# STM32H723 register map
File version: 1.6
CPU: CM7 r0p1, little endian, MPU, FPU, 4 interrupt priority bits
Registers are 32-bit, read-write, reset 0x0 unless marked. A register's access mark holds for its fields unless they carry their own. Offsets are from the block's base; [hi:lo] are bit positions; {n}, {i} and the like mark numbered series; 'fields as' and 'values as' point back to an identical list.

## RCC — Reset and clock control
Base 0x58024400
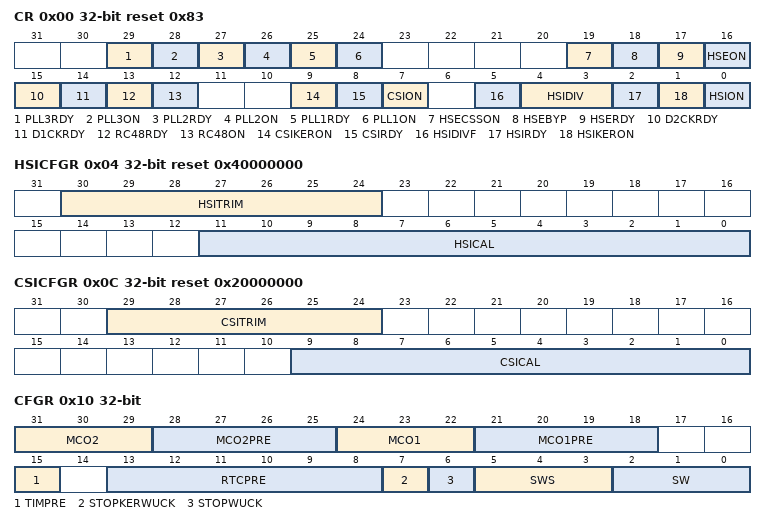
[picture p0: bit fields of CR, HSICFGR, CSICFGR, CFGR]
0x00 CR reset 0x83 — clock control register
  [29] PLL3RDY — PLL3 clock ready flag
  [28] PLL3ON — PLL3 enable
  [27] PLL2RDY — PLL2 clock ready flag
  [26] PLL2ON — PLL2 enable
  [25] PLL1RDY — PLL1 clock ready flag
  [24] PLL1ON — PLL1 enable
  [19] HSECSSON — HSE Clock Security System enable
  [18] HSEBYP — HSE clock bypass
  [17] HSERDY — HSE clock ready flag
  [16] HSEON — HSE clock enable
  [15] D2CKRDY — D2 domain clocks ready flag
  [14] D1CKRDY — D1 domain clocks ready flag
  [13] RC48RDY — RC48 clock ready flag
  [12] RC48ON — RC48 clock enable
  [9] CSIKERON — CSI clock enable in Stop mode
  [8] CSIRDY — CSI clock ready flag
  [7] CSION — CSI clock enable
  [5] HSIDIVF — HSI divider flag
  [4:3] HSIDIV — HSI clock divider
  [2] HSIRDY — HSI clock ready flag
  [1] HSIKERON — High Speed Internal clock enable in Stop mode
  [0] HSION — Internal high-speed clock enable
0x04 HSICFGR access per field reset 0x40000000 (reset mask 0xFFFFF000) — RCC HSI calibration register
  [30:24] HSITRIM rw — HSI clock trimming Set by software to adjust calibration. HSITRIM field is added to the engineering option bytes loaded during reset phase (FLASH_HSI_opt) in order to form the calibration trimming value. HSICALÂ =Â HSITRIMÂ +Â FLASH_HSI_opt. Note: The reset value of the field is 0x40.
  [11:0] HSICAL ro — HSI clock calibration Set by hardware by option byte loading during system reset nreset. Adjusted by software through trimming bits HSITRIM. This field represents the sum of engineering option byte calibration value and HSITRIM bits value.
0x08 CRRCR ro (reset mask 0xFFFFF000) — RCC clock recovery RC register
  [9:0] HSI48CAL — Internal RC 48 MHz clock calibration Set by hardware by option byte loading during system reset nreset. Read-only.
0x0C CSICFGR access per field reset 0x20000000 (reset mask 0xFFFFF000) — RCC CSI calibration register
  [29:24] CSITRIM rw — CSI clock trimming Set by software to adjust calibration. CSITRIM field is added to the engineering option bytes loaded during reset phase (FLASH_CSI_opt) in order to form the calibration trimming value. CSICALÂ =Â CSITRIMÂ +Â FLASH_CSI_opt. Note: The reset value of the field is 0x20.
  [9:0] CSICAL ro — CSI clock calibration Set by hardware by option byte loading during system reset nreset. Adjusted by software through trimming bits CSITRIM. This field represents the sum of engineering option byte calibration value and CSITRIM bits value.
0x10 CFGR — RCC Clock Configuration Register
  [31:29] MCO2 — Micro-controller clock output 2
  [28:25] MCO2PRE — MCO2 prescaler
  [24:22] MCO1 — Micro-controller clock output 1
  [21:18] MCO1PRE — MCO1 prescaler
  [15] TIMPRE — Timers clocks prescaler selection
  [13:8] RTCPRE — HSE division factor for RTC clock
  [7] STOPKERWUCK — Kernel clock selection after a wake up from system Stop
  [6] STOPWUCK — System clock selection after a wake up from system Stop
  [5:3] SWS — System clock switch status
  [2:0] SW — System clock switch
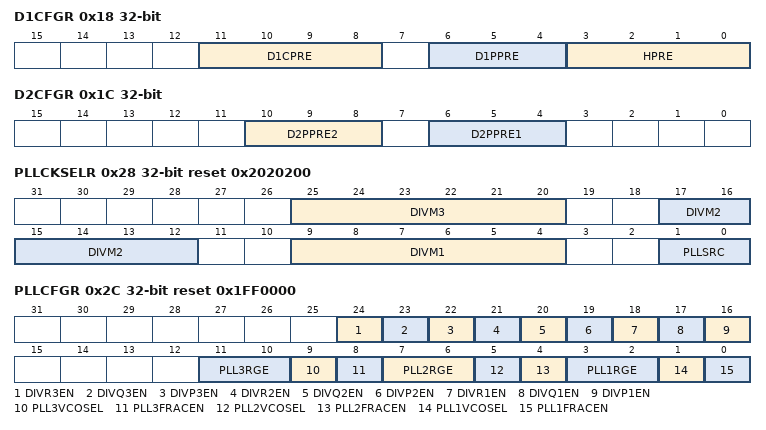
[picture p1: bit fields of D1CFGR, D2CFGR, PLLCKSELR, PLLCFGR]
0x18 D1CFGR — RCC Domain 1 Clock Configuration Register
  [11:8] D1CPRE — D1 domain Core prescaler
  [6:4] D1PPRE — D1 domain APB3 prescaler
  [3:0] HPRE — D1 domain AHB prescaler
0x1C D2CFGR — RCC Domain 2 Clock Configuration Register
  [10:8] D2PPRE2 — D2 domain APB2 prescaler
  [6:4] D2PPRE1 — D2 domain APB1 prescaler
0x20 D3CFGR — RCC Domain 3 Clock Configuration Register
  [6:4] D3PPRE — D3 domain APB4 prescaler
0x28 PLLCKSELR reset 0x2020200 — RCC PLLs Clock Source Selection Register
  [25:20] DIVM3 — Prescaler for PLL3
  [17:12] DIVM2 — Prescaler for PLL2
  [9:4] DIVM1 — Prescaler for PLL1
  [1:0] PLLSRC — DIVMx and PLLs clock source selection
0x2C PLLCFGR reset 0x1FF0000 — RCC PLLs Configuration Register
  [24] DIVR3EN — PLL3 DIVR divider output enable
  [23] DIVQ3EN — PLL3 DIVQ divider output enable
  [22] DIVP3EN — PLL3 DIVP divider output enable
  [21] DIVR2EN — PLL2 DIVR divider output enable
  [20] DIVQ2EN — PLL2 DIVQ divider output enable
  [19] DIVP2EN — PLL2 DIVP divider output enable
  [18] DIVR1EN — PLL1 DIVR divider output enable
  [17] DIVQ1EN — PLL1 DIVQ divider output enable
  [16] DIVP1EN — PLL1 DIVP divider output enable
  [11:10] PLL3RGE — PLL3 input frequency range
  [9] PLL3VCOSEL — PLL3 VCO selection
  [8] PLL3FRACEN — PLL3 fractional latch enable
  [7:6] PLL2RGE — PLL2 input frequency range
  [5] PLL2VCOSEL — PLL2 VCO selection
  [4] PLL2FRACEN — PLL2 fractional latch enable
  [3:2] PLL1RGE — PLL1 input frequency range
  [1] PLL1VCOSEL — PLL1 VCO selection
  [0] PLL1FRACEN — PLL1 fractional latch enable
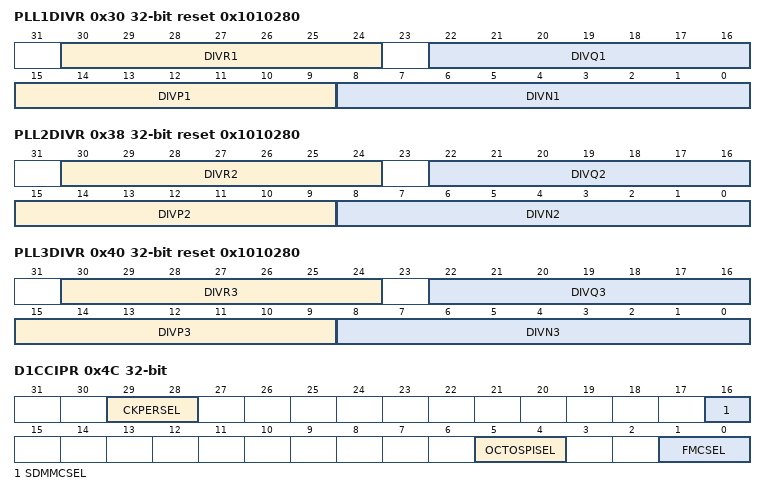
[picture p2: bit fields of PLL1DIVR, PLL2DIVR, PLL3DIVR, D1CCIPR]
0x30 PLL1DIVR reset 0x1010280 — RCC PLL1 Dividers Configuration Register
  [30:24] DIVR1 — PLL1 DIVR division factor
  [22:16] DIVQ1 — PLL1 DIVQ division factor
  [15:9] DIVP1 — PLL1 DIVP division factor
  [8:0] DIVN1 — Multiplication factor for PLL1 VCO
0x34 PLL1FRACR — RCC PLL1 Fractional Divider Register
  [15:3] FRACN1 — Fractional part of the multiplication factor for PLL1 VCO
0x38 PLL2DIVR reset 0x1010280 — RCC PLL2 Dividers Configuration Register
  [30:24] DIVR2 — PLL1 DIVR division factor
  [22:16] DIVQ2 — PLL1 DIVQ division factor
  [15:9] DIVP2 — PLL1 DIVP division factor
  [8:0] DIVN2 — Multiplication factor for PLL1 VCO
0x3C PLL2FRACR — RCC PLL2 Fractional Divider Register
  [15:3] FRACN2 — Fractional part of the multiplication factor for PLL VCO
0x40 PLL3DIVR reset 0x1010280 — RCC PLL3 Dividers Configuration Register
  [30:24] DIVR3 — PLL DIVR division factor
  [22:16] DIVQ3 — PLL DIVQ division factor
  [15:9] DIVP3 — PLL DIVP division factor
  [8:0] DIVN3 — Multiplication factor for PLL1 VCO
0x44 PLL3FRACR — RCC PLL3 Fractional Divider Register
  [15:3] FRACN3 — Fractional part of the multiplication factor for PLL3 VCO
0x4C D1CCIPR — RCC Domain 1 Kernel Clock Configuration Register
  [29:28] CKPERSEL — per_ck clock source selection
  [16] SDMMCSEL — SDMMC kernel clock source selection
  [5:4] OCTOSPISEL — QUADSPI kernel clock source selection
  [1:0] FMCSEL — FMC kernel clock source selection
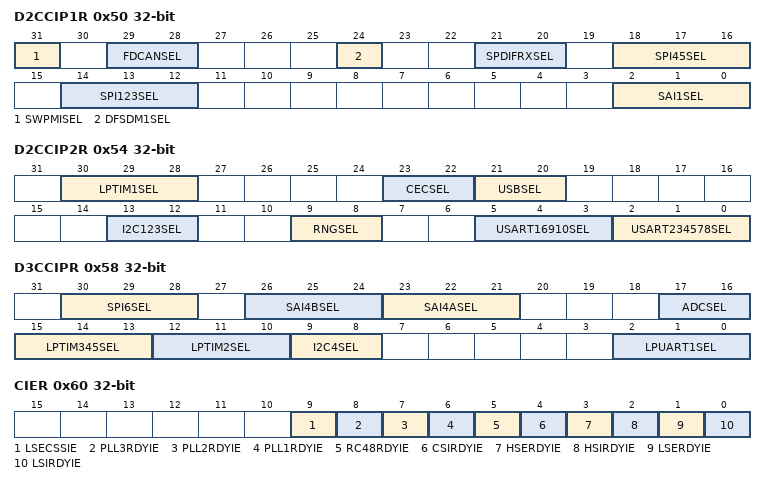
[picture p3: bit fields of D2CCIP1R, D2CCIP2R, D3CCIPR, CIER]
0x50 D2CCIP1R — RCC Domain 2 Kernel Clock Configuration Register
  [31] SWPMISEL — SWPMI kernel clock source selection
  [29:28] FDCANSEL — FDCAN kernel clock source selection
  [24] DFSDM1SEL — DFSDM1 kernel Clk clock source selection
  [21:20] SPDIFRXSEL — SPDIFRX kernel clock source selection
  [18:16] SPI45SEL — SPI4 and 5 kernel clock source selection
  [14:12] SPI123SEL — SPI/I2S1,2 and 3 kernel clock source selection
  [2:0] SAI1SEL — SAI1 and DFSDM1 kernel Aclk clock source selection
0x54 D2CCIP2R — RCC Domain 2 Kernel Clock Configuration Register
  [30:28] LPTIM1SEL — LPTIM1 kernel clock source selection
  [23:22] CECSEL — HDMI-CEC kernel clock source selection
  [21:20] USBSEL — USBOTG 1 and 2 kernel clock source selection
  [13:12] I2C123SEL — I2C1,2,3 kernel clock source selection
  [9:8] RNGSEL — RNG kernel clock source selection
  [5:3] USART16910SEL — USART1 and 6 kernel clock source selection
  [2:0] USART234578SEL — USART2/3, UART4,5, 7/8 (APB1) kernel clock source selection
0x58 D3CCIPR — RCC Domain 3 Kernel Clock Configuration Register
  [30:28] SPI6SEL — SPI6 kernel clock source selection
  [26:24] SAI4BSEL — Sub-Block B of SAI4 kernel clock source selection
  [23:21] SAI4ASEL — Sub-Block A of SAI4 kernel clock source selection
  [17:16] ADCSEL — SAR ADC kernel clock source selection
  [15:13] LPTIM345SEL — LPTIM3,4,5 kernel clock source selection
  [12:10] LPTIM2SEL — LPTIM2 kernel clock source selection
  [9:8] I2C4SEL — I2C4 kernel clock source selection
  [2:0] LPUART1SEL — LPUART1 kernel clock source selection
0x60 CIER — RCC Clock Source Interrupt Enable Register
  [9] LSECSSIE — LSE clock security system Interrupt Enable
  [8] PLL3RDYIE — PLL3 ready Interrupt Enable
  [7] PLL2RDYIE — PLL2 ready Interrupt Enable
  [6] PLL1RDYIE — PLL1 ready Interrupt Enable
  [5] RC48RDYIE — RC48 ready Interrupt Enable
  [4] CSIRDYIE — CSI ready Interrupt Enable
  [3] HSERDYIE — HSE ready Interrupt Enable
  [2] HSIRDYIE — HSI ready Interrupt Enable
  [1] LSERDYIE — LSE ready Interrupt Enable
  [0] LSIRDYIE — LSI ready Interrupt Enable
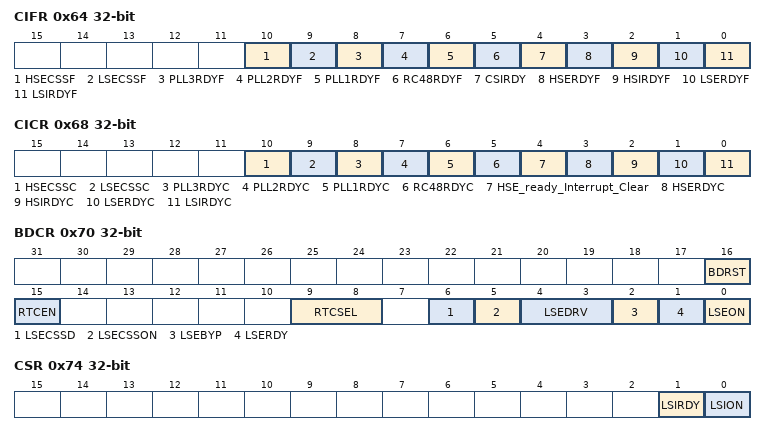
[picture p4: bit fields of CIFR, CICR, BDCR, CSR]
0x64 CIFR — RCC Clock Source Interrupt Flag Register
  [10] HSECSSF — HSE clock security system Interrupt Flag
  [9] LSECSSF — LSE clock security system Interrupt Flag
  [8] PLL3RDYF — PLL3 ready Interrupt Flag
  [7] PLL2RDYF — PLL2 ready Interrupt Flag
  [6] PLL1RDYF — PLL1 ready Interrupt Flag
  [5] RC48RDYF — RC48 ready Interrupt Flag
  [4] CSIRDY — CSI ready Interrupt Flag
  [3] HSERDYF — HSE ready Interrupt Flag
  [2] HSIRDYF — HSI ready Interrupt Flag
  [1] LSERDYF — LSE ready Interrupt Flag
  [0] LSIRDYF — LSI ready Interrupt Flag
0x68 CICR — RCC Clock Source Interrupt Clear Register
  [10] HSECSSC — HSE clock security system Interrupt Clear
  [9] LSECSSC — LSE clock security system Interrupt Clear
  [8] PLL3RDYC — PLL3 ready Interrupt Clear
  [7] PLL2RDYC — PLL2 ready Interrupt Clear
  [6] PLL1RDYC — PLL1 ready Interrupt Clear
  [5] RC48RDYC — RC48 ready Interrupt Clear
  [4] HSE_ready_Interrupt_Clear — CSI ready Interrupt Clear
  [3] HSERDYC — HSE ready Interrupt Clear
  [2] HSIRDYC — HSI ready Interrupt Clear
  [1] LSERDYC — LSE ready Interrupt Clear
  [0] LSIRDYC — LSI ready Interrupt Clear
0x70 BDCR — RCC Backup Domain Control Register
  [16] BDRST — Backup domain software reset
  [15] RTCEN — RTC clock enable
  [9:8] RTCSEL — RTC clock source selection
  [6] LSECSSD — LSE clock security system failure detection
  [5] LSECSSON — LSE clock security system enable
  [4:3] LSEDRV — LSE oscillator driving capability
  [2] LSEBYP — LSE oscillator bypass
  [1] LSERDY — LSE oscillator ready
  [0] LSEON — LSE oscillator enabled
0x74 CSR — RCC Clock Control and Status Register
  [1] LSIRDY — LSI oscillator ready
  [0] LSION — LSI oscillator enable
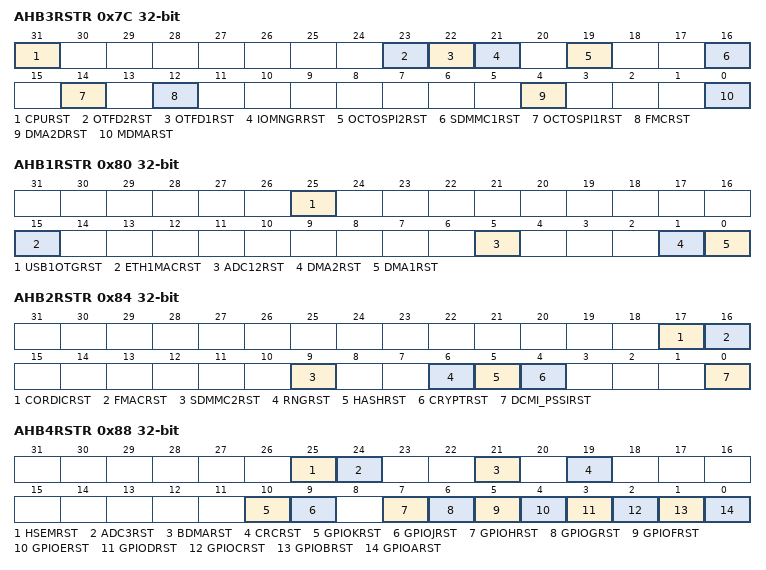
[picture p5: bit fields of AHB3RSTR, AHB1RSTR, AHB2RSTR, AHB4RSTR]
0x7C AHB3RSTR — RCC AHB3 Reset Register
  [31] CPURST — CPU reset
  [23] OTFD2RST — OTFD2 reset Set and reset by software Take care that resetting the OTFD means loosing the decryption key loaded during secure boot.
  [22] OTFD1RST — OTFD1 reset Set and reset by software Take care that resetting the OTFD means loosing the decryption key loaded during secure boot.
  [21] IOMNGRRST — OCTOSPIM reset Set and reset by software
  [19] OCTOSPI2RST — OCTOSPI2 and OCTOSPI2 delay block reset Set and reset by software
  [16] SDMMC1RST — SDMMC1 and SDMMC1 delay block reset
  [14] OCTOSPI1RST — QUADSPI and QUADSPI delay block reset
  [12] FMCRST — FMC block reset
  [4] DMA2DRST — DMA2D block reset
  [0] MDMARST — MDMA block reset
0x80 AHB1RSTR — RCC AHB1 Peripheral Reset Register
  [25] USB1OTGRST — USB1OTG block reset
  [15] ETH1MACRST — ETH1MAC block reset
  [5] ADC12RST — ADC1&2 block reset
  [1] DMA2RST — DMA2 block reset
  [0] DMA1RST — DMA1 block reset
0x84 AHB2RSTR — RCC AHB2 Peripheral Reset Register
  [17] CORDICRST — CORDIC coprocessor block reset
  [16] FMACRST — FMAC reset
  [9] SDMMC2RST — SDMMC2 and SDMMC2 Delay block reset
  [6] RNGRST — Random Number Generator block reset
  [5] HASHRST — Hash block reset
  [4] CRYPTRST — Cryptography block reset
  [0] DCMI_PSSIRST
0x88 AHB4RSTR — RCC AHB4 Peripheral Reset Register
  [25] HSEMRST — HSEM block reset
  [24] ADC3RST — ADC3 block reset
  [21] BDMARST — BDMA block reset
  [19] CRCRST — CRC block reset
  [10] GPIOKRST — GPIO block reset
  [9] GPIOJRST — GPIO block reset
  [7] GPIOHRST — GPIO block reset
  [6] GPIOGRST — GPIO block reset
  [5] GPIOFRST — GPIO block reset
  [4] GPIOERST — GPIO block reset
  [3] GPIODRST — GPIO block reset
  [2] GPIOCRST — GPIO block reset
  [1] GPIOBRST — GPIO block reset
  [0] GPIOARST — GPIO block reset
0x8C APB3RSTR — RCC APB3 Peripheral Reset Register
  [3] LTDCRST — LTDC block reset
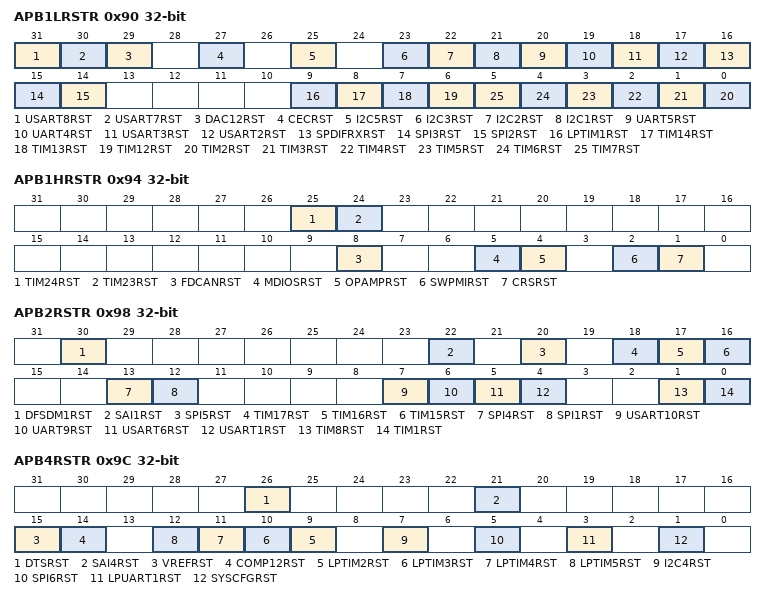
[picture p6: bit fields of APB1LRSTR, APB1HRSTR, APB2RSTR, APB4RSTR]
0x90 APB1LRSTR — RCC APB1 Peripheral Reset Register
  [31] USART8RST — USART8 block reset
  [30] USART7RST — USART7 block reset
  [29] DAC12RST — DAC1 and 2 Blocks Reset
  [27] CECRST — HDMI-CEC block reset
  [25] I2C5RST — I2C5 block reset
  [23] I2C3RST — I2C3 block reset
  [22] I2C2RST — I2C2 block reset
  [21] I2C1RST — I2C1 block reset
  [20] UART5RST — UART5 block reset
  [19] UART4RST — UART4 block reset
  [18] USART3RST — USART3 block reset
  [17] USART2RST — USART2 block reset
  [16] SPDIFRXRST — SPDIFRX block reset
  [15] SPI3RST — SPI3 block reset
  [14] SPI2RST — SPI2 block reset
  [9] LPTIM1RST — TIM block reset
  [8] TIM14RST — TIM block reset
  [7] TIM13RST — TIM block reset
  [6] TIM12RST — TIM block reset
  [n-2] TIM{n}RST (n=2..7) — TIM block reset
0x94 APB1HRSTR — RCC APB1 Peripheral Reset Register
  [25] TIM24RST — TIM24 block resett
  [24] TIM23RST — TIM23 block reset
  [8] FDCANRST — FDCAN block reset
  [5] MDIOSRST — MDIOS block reset
  [4] OPAMPRST — OPAMP block reset
  [2] SWPMIRST — SWPMI block reset
  [1] CRSRST — Clock Recovery System reset
0x98 APB2RSTR — RCC APB2 Peripheral Reset Register
  [30] DFSDM1RST — DFSDM1 block reset Set and reset by software.
  [22] SAI1RST — SAI1 block reset
  [20] SPI5RST — SPI5 block reset
  [18] TIM17RST — TIM17 block reset
  [17] TIM16RST — TIM16 block reset
  [16] TIM15RST — TIM15 block reset
  [13] SPI4RST — SPI4 block reset
  [12] SPI1RST — SPI1 block reset
  [7] USART10RST — USART10 block reset Set and reset by software.
  [6] UART9RST — UART9 block reset Set and reset by software.
  [5] USART6RST — USART6 block reset
  [4] USART1RST — USART1 block reset
  [1] TIM8RST — TIM8 block reset
  [0] TIM1RST — TIM1 block reset
0x9C APB4RSTR — RCC APB4 Peripheral Reset Register
  [26] DTSRST — Digital temperature sensor block reset Set and reset by software.
  [21] SAI4RST — SAI4 block reset
  [15] VREFRST — VREF block reset
  [14] COMP12RST — COMP12 Blocks Reset
  [n+7] LPTIM{n}RST (n=2..5) — LPTIM{n} block reset
  [7] I2C4RST — I2C4 block reset
  [5] SPI6RST — SPI6 block reset
  [3] LPUART1RST — LPUART1 block reset
  [1] SYSCFGRST — SYSCFG block reset
0xA0 GCR — RCC Global Control Register
  [0] WW1RSC — WWDG1 reset scope control
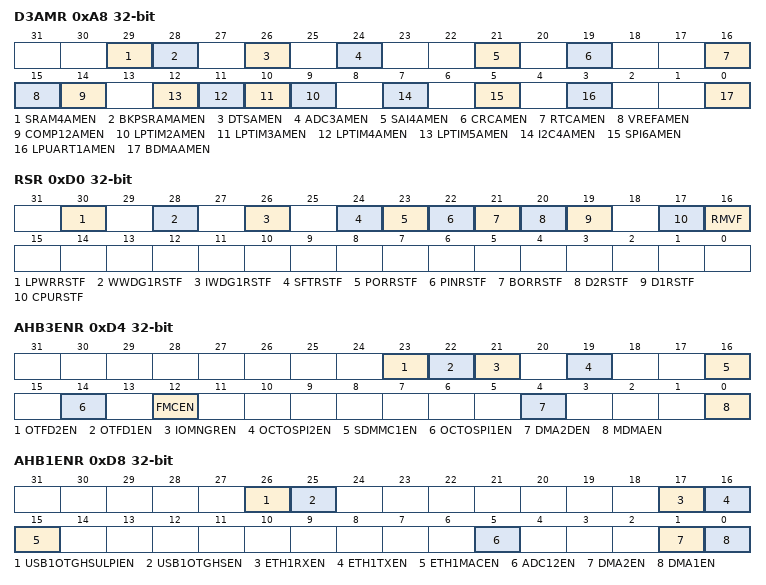
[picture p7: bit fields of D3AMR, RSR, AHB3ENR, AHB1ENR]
0xA8 D3AMR — RCC D3 Autonomous mode Register
  [29] SRAM4AMEN — SRAM4 Autonomous mode enable
  [28] BKPSRAMAMEN — Backup RAM Autonomous mode enable
  [26] DTSAMEN — Digital temperature sensor Autonomous mode enable Set and reset by software. Refer to for additional information.
  [24] ADC3AMEN — ADC3 Autonomous mode enable
  [21] SAI4AMEN — SAI4 Autonomous mode enable
  [19] CRCAMEN — CRC Autonomous mode enable
  [16] RTCAMEN — RTC Autonomous mode enable
  [15] VREFAMEN — VREF Autonomous mode enable
  [14] COMP12AMEN — COMP12 Autonomous mode enable
  [n+7] LPTIM{n}AMEN (n=2..5) — LPTIM{n} Autonomous mode enable
  [7] I2C4AMEN — I2C4 Autonomous mode enable
  [5] SPI6AMEN — SPI6 Autonomous mode enable
  [3] LPUART1AMEN — LPUART1 Autonomous mode enable
  [0] BDMAAMEN — BDMA and DMAMUX Autonomous mode enable
0xD0 RSR — RCC Reset Status Register
  [30] LPWRRSTF — Reset due to illegal D1 DStandby or CPU CStop flag
  [28] WWDG1RSTF — Window Watchdog reset flag
  [26] IWDG1RSTF — Independent Watchdog reset flag
  [24] SFTRSTF — System reset from CPU reset flag
  [23] PORRSTF — POR/PDR reset flag
  [22] PINRSTF — Pin reset flag (NRST)
  [21] BORRSTF — BOR reset flag
  [20] D2RSTF — D2 domain power switch reset flag
  [19] D1RSTF — D1 domain power switch reset flag
  [17] CPURSTF — CPU reset flag
  [16] RMVF — Remove reset flag
0xD4 AHB3ENR — RCC AHB3 Clock Register
  [23] OTFD2EN — OTFD2 clock enable Set and reset by software.
  [22] OTFD1EN — OTFD1 clock enable Set and reset by software.
  [21] IOMNGREN — OCTOSPIM clock enable Set and reset by software.
  [19] OCTOSPI2EN — OCTOSPI2 clock enable Set and reset by software.
  [16] SDMMC1EN — SDMMC1 and SDMMC1 Delay Clock Enable
  [14] OCTOSPI1EN — OCTOSPI1 and OCTOSPI1 delay clock enable
  [12] FMCEN — FMC Peripheral Clocks Enable
  [4] DMA2DEN — DMA2D Peripheral Clock Enable
  [0] MDMAEN — MDMA Peripheral Clock Enable
0xD8 AHB1ENR — RCC AHB1 Clock Register
  [26] USB1OTGHSULPIEN — USB_PHY1 Clocks Enable
  [25] USB1OTGHSEN — USB1OTG Peripheral Clocks Enable
  [17] ETH1RXEN — Ethernet Reception Clock Enable
  [16] ETH1TXEN — Ethernet Transmission Clock Enable
  [15] ETH1MACEN — Ethernet MAC bus interface Clock Enable
  [5] ADC12EN — ADC1/2 Peripheral Clocks Enable
  [1] DMA2EN — DMA2 Clock Enable
  [0] DMA1EN — DMA1 Clock Enable
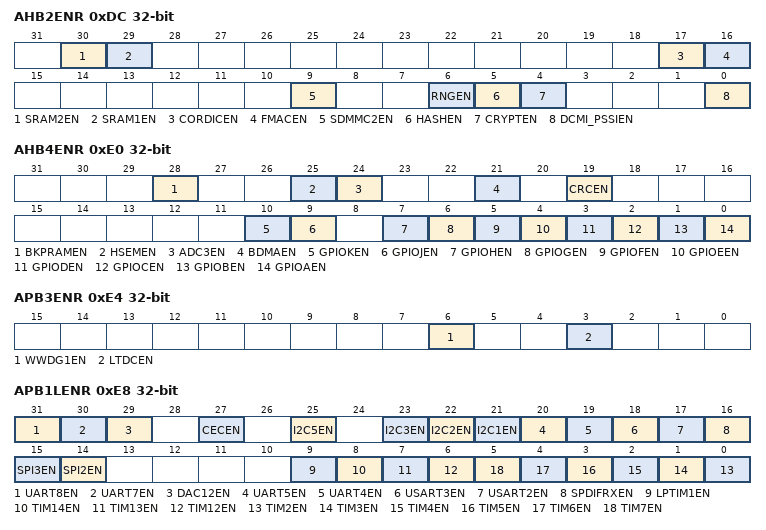
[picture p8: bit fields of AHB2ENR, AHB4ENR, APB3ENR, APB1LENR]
0xDC AHB2ENR — RCC AHB2 Clock Register
  [30] SRAM2EN — SRAM2 block enable
  [29] SRAM1EN — SRAM1 block enable
  [17] CORDICEN — CORDIC clock enable
  [16] FMACEN — FMAC clock enable
  [9] SDMMC2EN — SDMMC2 and SDMMC2 delay clock enable
  [6] RNGEN — RNG peripheral clocks enable
  [5] HASHEN — HASH peripheral clock enable
  [4] CRYPTEN — CRYPT peripheral clock enable
  [0] DCMI_PSSIEN — CAMITF peripheral clock enable
0xE0 AHB4ENR — RCC AHB4 Clock Register
  [28] BKPRAMEN — Backup RAM Clock Enable
  [25] HSEMEN — HSEM peripheral clock enable
  [24] ADC3EN — ADC3 Peripheral Clocks Enable
  [21] BDMAEN — BDMA and DMAMUX2 Clock Enable
  [19] CRCEN — CRC peripheral clock enable
  [10] GPIOKEN — 0GPIO peripheral clock enable
  [9] GPIOJEN — 0GPIO peripheral clock enable
  [7] GPIOHEN — 0GPIO peripheral clock enable
  [6] GPIOGEN — 0GPIO peripheral clock enable
  [5] GPIOFEN — 0GPIO peripheral clock enable
  [4] GPIOEEN — 0GPIO peripheral clock enable
  [3] GPIODEN — 0GPIO peripheral clock enable
  [2] GPIOCEN — 0GPIO peripheral clock enable
  [1] GPIOBEN — 0GPIO peripheral clock enable
  [0] GPIOAEN — 0GPIO peripheral clock enable
0xE4 APB3ENR — RCC APB3 Clock Register
  [6] WWDG1EN — WWDG1 Clock Enable
  [3] LTDCEN — LTDC peripheral clock enable
0xE8 APB1LENR — RCC APB1 Clock Register
  [31] UART8EN — UART8 Peripheral Clocks Enable
  [30] UART7EN — UART7 Peripheral Clocks Enable
  [29] DAC12EN — DAC1 and 2 peripheral clock enable
  [27] CECEN — HDMI-CEC peripheral clock enable
  [25] I2C5EN — I2C5 Peripheral Clocks Enable
  [23] I2C3EN — I2C3 Peripheral Clocks Enable
  [22] I2C2EN — I2C2 Peripheral Clocks Enable
  [21] I2C1EN — I2C1 Peripheral Clocks Enable
  [20] UART5EN — UART5 Peripheral Clocks Enable
  [19] UART4EN — UART4 Peripheral Clocks Enable
  [18] USART3EN — USART3 Peripheral Clocks Enable
  [17] USART2EN — USART2 Peripheral Clocks Enable
  [16] SPDIFRXEN — SPDIFRX Peripheral Clocks Enable
  [15] SPI3EN — SPI3 Peripheral Clocks Enable
  [14] SPI2EN — SPI2 Peripheral Clocks Enable
  [9] LPTIM1EN — LPTIM1 Peripheral Clocks Enable
  [8] TIM14EN — TIM peripheral clock enable
  [7] TIM13EN — TIM peripheral clock enable
  [6] TIM12EN — TIM peripheral clock enable
  [n-2] TIM{n}EN (n=2..7) — TIM peripheral clock enable
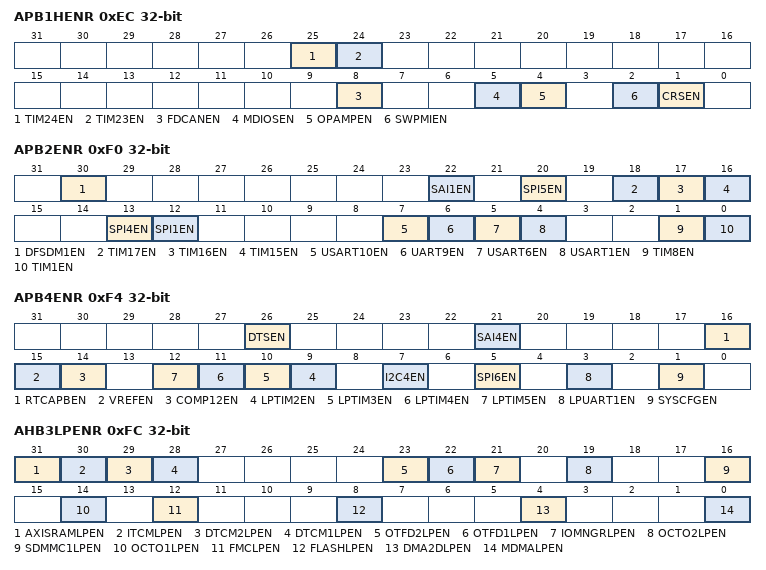
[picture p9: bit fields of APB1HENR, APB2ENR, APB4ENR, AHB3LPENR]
0xEC APB1HENR — RCC APB1 Clock Register
  [25] TIM24EN — TIM24 Peripheral Clocks Enable
  [24] TIM23EN — TIM23 Peripheral Clocks Enable
  [8] FDCANEN — FDCAN Peripheral Clocks Enable
  [5] MDIOSEN — MDIOS peripheral clock enable
  [4] OPAMPEN — OPAMP peripheral clock enable
  [2] SWPMIEN — SWPMI Peripheral Clocks Enable
  [1] CRSEN — Clock Recovery System peripheral clock enable
0xF0 APB2ENR — RCC APB2 Clock Register
  [30] DFSDM1EN — DFSDM1 peripheral clocks enable Set and reset by software. DFSDM1 peripheral clocks are the kernel clocks selected by SAI1SEL and DFSDM1SEL and provided to Aclk and clk inputs respectively,
  [22] SAI1EN — SAI1 Peripheral Clocks Enable
  [20] SPI5EN — SPI5 Peripheral Clocks Enable
  [18] TIM17EN — TIM17 peripheral clock enable
  [17] TIM16EN — TIM16 peripheral clock enable
  [16] TIM15EN — TIM15 peripheral clock enable Set and reset by software.
  [13] SPI4EN — SPI4 Peripheral Clocks Enable
  [12] SPI1EN — SPI1 Peripheral Clocks Enable
  [7] USART10EN — USART10 peripheral clocks enable Set and reset by software. The peripheral clocks of the USART10 are the kernel clock selected by USART16910SEL and provided to UCKL input, and the rcc_pclk2 bus interface clock.
  [6] UART9EN — UART9 peripheral clocks enable Set and reset by software. The peripheral clocks of the UART9 are the kernel clock selected by USART16910SEL and provided to UCKL input, and the rcc_pclk2 bus interface clock.
  [5] USART6EN — USART6 Peripheral Clocks Enable
  [4] USART1EN — USART1 Peripheral Clocks Enable
  [1] TIM8EN — TIM8 peripheral clock enable
  [0] TIM1EN — TIM1 peripheral clock enable
0xF4 APB4ENR — RCC APB4 Clock Register
  [26] DTSEN — Digital temperature sensor peripheral clock enable Set and reset by software.
  [21] SAI4EN — SAI4 Peripheral Clocks Enable
  [16] RTCAPBEN — RTC APB Clock Enable
  [15] VREFEN — VREF peripheral clock enable
  [14] COMP12EN — COMP1/2 peripheral clock enable
  [n+7] LPTIM{n}EN (n=2..5) — LPTIM{n} Peripheral Clocks Enable
  [7] I2C4EN — I2C4 Peripheral Clocks Enable
  [5] SPI6EN — SPI6 Peripheral Clocks Enable
  [3] LPUART1EN — LPUART1 Peripheral Clocks Enable
  [1] SYSCFGEN — SYSCFG peripheral clock enable
0xFC AHB3LPENR — RCC AHB3 Sleep Clock Register
  [31] AXISRAMLPEN — AXISRAM Block Clock Enable During CSleep mode
  [30] ITCMLPEN — D1ITCM Block Clock Enable During CSleep mode
  [29] DTCM2LPEN — D1 DTCM2 Block Clock Enable During CSleep mode
  [28] DTCM1LPEN — D1DTCM1 Block Clock Enable During CSleep mode
  [23] OTFD2LPEN — OTFD2 block clock enable during CSleep mode Set and reset by software.
  [22] OTFD1LPEN — OTFD1 block clock enable during CSleep mode Set and reset by software.
  [21] IOMNGRLPEN — OCTOSPIM block clock enable during CSleep mode Set and reset by software.
  [19] OCTO2LPEN — OCTOSPI2 and OCTOSPI2 delay clock enable during CSleep mode Set and reset by software.
  [16] SDMMC1LPEN — SDMMC1 and SDMMC1 Delay Clock Enable During CSleep Mode
  [14] OCTO1LPEN — QUADSPI and QUADSPI Delay Clock Enable During CSleep Mode
  [12] FMCLPEN — FMC Peripheral Clocks Enable During CSleep Mode
  [8] FLASHLPEN — Flash interface Clock Enable During CSleep Mode
  [4] DMA2DLPEN — DMA2D Clock Enable During CSleep Mode
  [0] MDMALPEN — MDMA Clock Enable During CSleep Mode
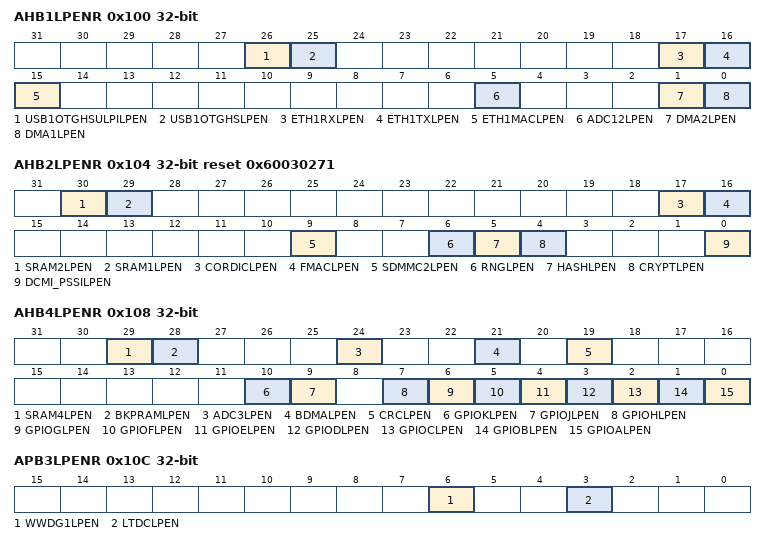
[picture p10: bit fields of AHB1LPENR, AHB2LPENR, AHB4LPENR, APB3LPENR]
0x100 AHB1LPENR — RCC AHB1 Sleep Clock Register
  [26] USB1OTGHSULPILPEN — USB_PHY1 clock enable during CSleep mode
  [25] USB1OTGHSLPEN — USB1OTG peripheral clock enable during CSleep mode
  [17] ETH1RXLPEN — Ethernet Reception Clock Enable During CSleep Mode
  [16] ETH1TXLPEN — Ethernet Transmission Clock Enable During CSleep Mode
  [15] ETH1MACLPEN — Ethernet MAC bus interface Clock Enable During CSleep Mode
  [5] ADC12LPEN — ADC1/2 Peripheral Clocks Enable During CSleep Mode
  [1] DMA2LPEN — DMA2 Clock Enable During CSleep Mode
  [0] DMA1LPEN — DMA1 Clock Enable During CSleep Mode
0x104 AHB2LPENR reset 0x60030271 — RCC AHB2 Sleep Clock Register
  [30] SRAM2LPEN — SRAM2 Clock Enable During CSleep Mode
  [29] SRAM1LPEN — SRAM1 Clock Enable During CSleep Mode
  [17] CORDICLPEN — CORDIC peripheral clock enable during CSleep mode
  [16] FMACLPEN — FMAC peripheral clock enable during CSleep mode
  [9] SDMMC2LPEN — SDMMC2 and SDMMC2 Delay Clock Enable During CSleep Mode
  [6] RNGLPEN — RNG peripheral clock enable during CSleep mode
  [5] HASHLPEN — HASH peripheral clock enable during CSleep mode
  [4] CRYPTLPEN — CRYPT peripheral clock enable during CSleep mode
  [0] DCMI_PSSILPEN
0x108 AHB4LPENR — RCC AHB4 Sleep Clock Register
  [29] SRAM4LPEN — SRAM4 Clock Enable During CSleep Mode
  [28] BKPRAMLPEN — Backup RAM Clock Enable During CSleep Mode
  [24] ADC3LPEN — ADC3 Peripheral Clocks Enable During CSleep Mode
  [21] BDMALPEN — BDMA Clock Enable During CSleep Mode
  [19] CRCLPEN — CRC peripheral clock enable during CSleep mode
  [10] GPIOKLPEN — GPIO peripheral clock enable during CSleep mode
  [9] GPIOJLPEN — GPIO peripheral clock enable during CSleep mode
  [7] GPIOHLPEN — GPIO peripheral clock enable during CSleep mode
  [6] GPIOGLPEN — GPIO peripheral clock enable during CSleep mode
  [5] GPIOFLPEN — GPIO peripheral clock enable during CSleep mode
  [4] GPIOELPEN — GPIO peripheral clock enable during CSleep mode
  [3] GPIODLPEN — GPIO peripheral clock enable during CSleep mode
  [2] GPIOCLPEN — GPIO peripheral clock enable during CSleep mode
  [1] GPIOBLPEN — GPIO peripheral clock enable during CSleep mode
  [0] GPIOALPEN — GPIO peripheral clock enable during CSleep mode
0x10C APB3LPENR — RCC APB3 Sleep Clock Register
  [6] WWDG1LPEN — WWDG1 Clock Enable During CSleep Mode
  [3] LTDCLPEN — LTDC peripheral clock enable during CSleep mode
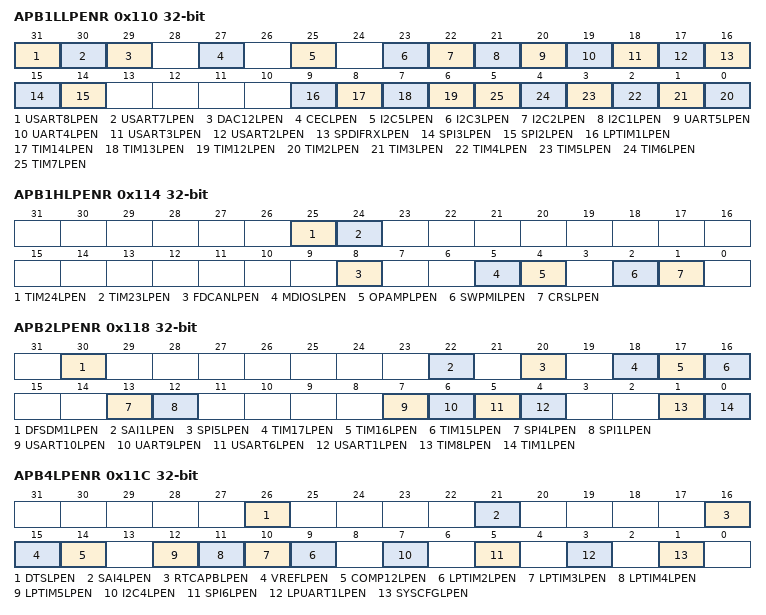
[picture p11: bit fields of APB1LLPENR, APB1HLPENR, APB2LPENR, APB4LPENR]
0x110 APB1LLPENR — RCC APB1 Low Sleep Clock Register
  [31] USART8LPEN — USART8 Peripheral Clocks Enable During CSleep Mode
  [30] USART7LPEN — USART7 Peripheral Clocks Enable During CSleep Mode
  [29] DAC12LPEN — DAC1/2 peripheral clock enable during CSleep mode
  [27] CECLPEN — CEC Peripheral Clocks Enable During CSleep Mode
  [25] I2C5LPEN — I2C5 Peripheral Clocks Enable During CSleep Mode
  [23] I2C3LPEN — I2C3 Peripheral Clocks Enable During CSleep Mode
  [22] I2C2LPEN — I2C2 Peripheral Clocks Enable During CSleep Mode
  [21] I2C1LPEN — I2C1 Peripheral Clocks Enable During CSleep Mode
  [20] UART5LPEN — UART5 Peripheral Clocks Enable During CSleep Mode
  [19] UART4LPEN — UART4 Peripheral Clocks Enable During CSleep Mode
  [18] USART3LPEN — USART3 Peripheral Clocks Enable During CSleep Mode
  [17] USART2LPEN — USART2 Peripheral Clocks Enable During CSleep Mode
  [16] SPDIFRXLPEN — SPDIFRX Peripheral Clocks Enable During CSleep Mode
  [15] SPI3LPEN — SPI3 Peripheral Clocks Enable During CSleep Mode
  [14] SPI2LPEN — SPI2 Peripheral Clocks Enable During CSleep Mode
  [9] LPTIM1LPEN — LPTIM1 Peripheral Clocks Enable During CSleep Mode
  [8] TIM14LPEN — TIM14 peripheral clock enable during CSleep mode
  [7] TIM13LPEN — TIM13 peripheral clock enable during CSleep mode
  [6] TIM12LPEN — TIM12 peripheral clock enable during CSleep mode
  [n-2] TIM{n}LPEN (n=2..7) — TIM{n} peripheral clock enable during CSleep mode
0x114 APB1HLPENR — RCC APB1 High Sleep Clock Register
  [25] TIM24LPEN — TIM24 Peripheral Clocks Enable During CSleep Mode
  [24] TIM23LPEN — TIM23 Peripheral Clocks Enable During CSleep Mode
  [8] FDCANLPEN — FDCAN Peripheral Clocks Enable During CSleep Mode
  [5] MDIOSLPEN — MDIOS peripheral clock enable during CSleep mode
  [4] OPAMPLPEN — OPAMP peripheral clock enable during CSleep mode
  [2] SWPMILPEN — SWPMI Peripheral Clocks Enable During CSleep Mode
  [1] CRSLPEN — Clock Recovery System peripheral clock enable during CSleep mode
0x118 APB2LPENR — RCC APB2 Sleep Clock Register
  [30] DFSDM1LPEN — DFSDM1 peripheral clocks enable during CSleep mode Set and reset by software. DFSDM1 peripheral clocks are the kernel clocks selected by SAI1SEL and DFSDM1SEL and provided to Aclk and clk inputs respectively, and the rcc_pclk2 bus interface clock.
  [22] SAI1LPEN — SAI1 Peripheral Clocks Enable During CSleep Mode
  [20] SPI5LPEN — SPI5 Peripheral Clocks Enable During CSleep Mode
  [18] TIM17LPEN — TIM17 peripheral clock enable during CSleep mode
  [17] TIM16LPEN — TIM16 peripheral clock enable during CSleep mode
  [16] TIM15LPEN — TIM15 peripheral clock enable during CSleep mode
  [13] SPI4LPEN — SPI4 Peripheral Clocks Enable During CSleep Mode
  [12] SPI1LPEN — SPI1 Peripheral Clocks Enable During CSleep Mode
  [7] USART10LPEN — USART10 peripheral clock enable during CSleep mode Set and reset by software. The peripheral clocks of the USART10 are the kernel clock selected by USART16910SEL and provided to usart_ker_ck input, and the rcc_pclk2 bus interface clock.
  [6] UART9LPEN — UART9 peripheral clock enable during CSleep mode Set and reset by software. The peripheral clocks of the UART9 are the kernel clock selected by USART16910SEL and provided to usart_ker_ck input, and the rcc_pclk2 bus interface clock.
  [5] USART6LPEN — USART6 Peripheral Clocks Enable During CSleep Mode
  [4] USART1LPEN — USART1 Peripheral Clocks Enable During CSleep Mode
  [1] TIM8LPEN — TIM8 peripheral clock enable during CSleep mode
  [0] TIM1LPEN — TIM1 peripheral clock enable during CSleep mode
0x11C APB4LPENR — RCC APB4 Sleep Clock Register
  [26] DTSLPEN — Digital temperature sensor peripheral clock enable during CSleep mode
  [21] SAI4LPEN — SAI4 Peripheral Clocks Enable During CSleep Mode
  [16] RTCAPBLPEN — RTC APB Clock Enable During CSleep Mode
  [15] VREFLPEN — VREF peripheral clock enable during CSleep mode
  [14] COMP12LPEN — COMP1/2 peripheral clock enable during CSleep mode
  [n+7] LPTIM{n}LPEN (n=2..5) — LPTIM{n} Peripheral Clocks Enable During CSleep Mode
  [7] I2C4LPEN — I2C4 Peripheral Clocks Enable During CSleep Mode
  [5] SPI6LPEN — SPI6 Peripheral Clocks Enable During CSleep Mode
  [3] LPUART1LPEN — LPUART1 Peripheral Clocks Enable During CSleep Mode
  [1] SYSCFGLPEN — SYSCFG peripheral clock enable during CSleep mode
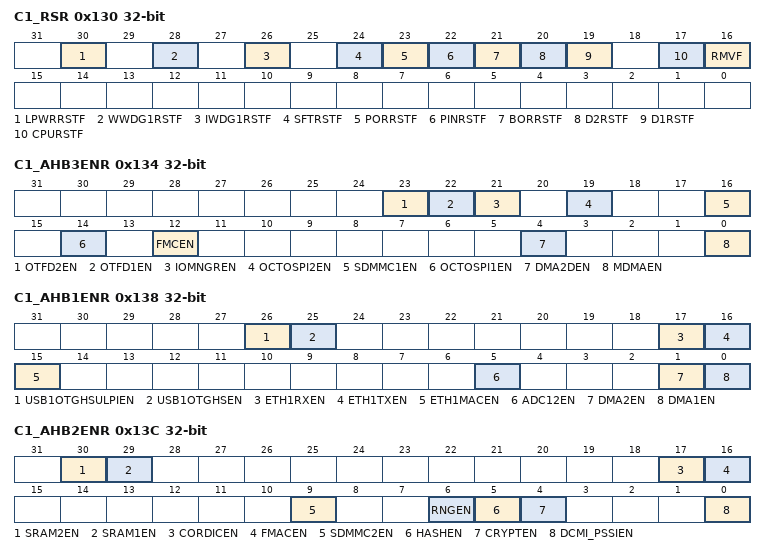
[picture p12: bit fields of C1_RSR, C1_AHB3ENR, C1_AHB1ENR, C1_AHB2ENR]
0x130 C1_RSR — RCC Reset Status Register
  fields as RSR
0x134 C1_AHB3ENR — RCC AHB3 Clock Register
  fields as AHB3ENR
0x138 C1_AHB1ENR — RCC AHB1 Clock Register
  fields as AHB1ENR
0x13C C1_AHB2ENR — RCC AHB2 Clock Register
  fields as AHB2ENR
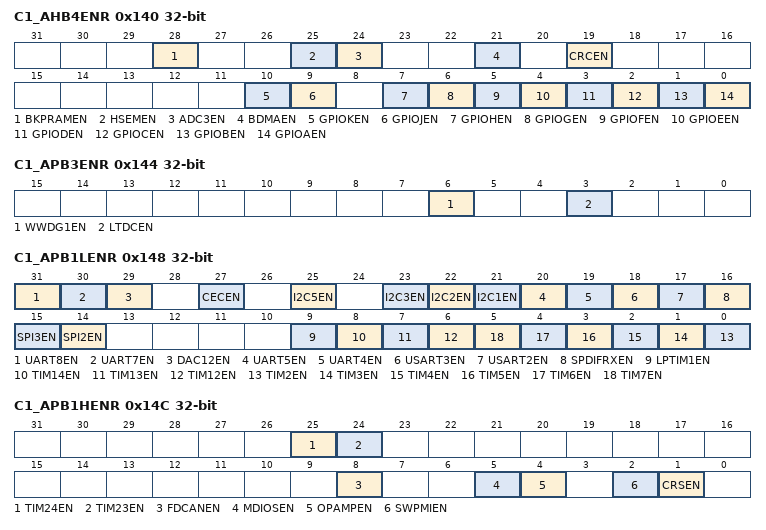
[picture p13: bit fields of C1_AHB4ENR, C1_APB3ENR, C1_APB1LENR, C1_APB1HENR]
0x140 C1_AHB4ENR — RCC AHB4 Clock Register
  fields as AHB4ENR
0x144 C1_APB3ENR — RCC APB3 Clock Register
  fields as APB3ENR
0x148 C1_APB1LENR — RCC APB1 Clock Register
  fields as APB1LENR
0x14C C1_APB1HENR — RCC APB1 Clock Register
  fields as APB1HENR
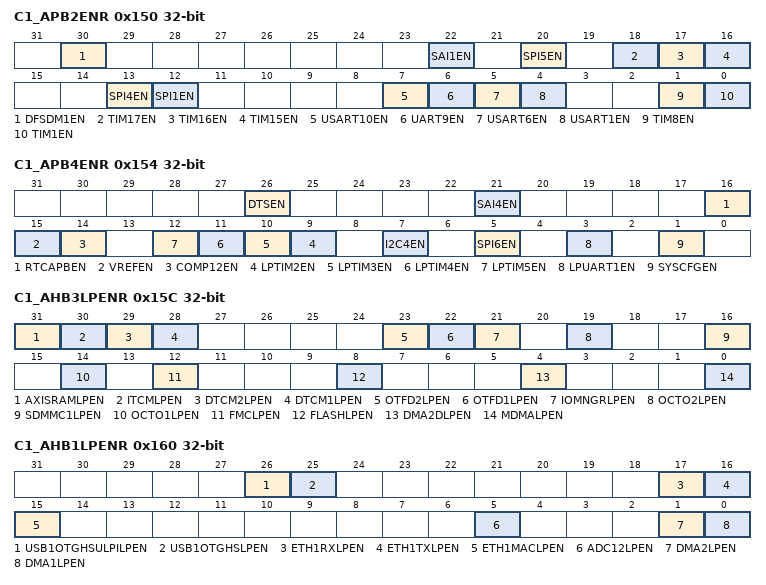
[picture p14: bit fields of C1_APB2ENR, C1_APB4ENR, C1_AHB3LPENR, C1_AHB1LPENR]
0x150 C1_APB2ENR — RCC APB2 Clock Register
  fields as APB2ENR
0x154 C1_APB4ENR — RCC APB4 Clock Register
  fields as APB4ENR
0x15C C1_AHB3LPENR — RCC AHB3 Sleep Clock Register
  fields as AHB3LPENR
0x160 C1_AHB1LPENR — RCC AHB1 Sleep Clock Register
  fields as AHB1LPENR
0x164 C1_AHB2LPENR reset 0x60030271 — RCC AHB2 Sleep Clock Register
  fields as AHB2LPENR
0x168 C1_AHB4LPENR — RCC AHB4 Sleep Clock Register
  fields as AHB4LPENR
0x16C C1_APB3LPENR — RCC APB3 Sleep Clock Register
  fields as APB3LPENR
0x170 C1_APB1LLPENR — RCC APB1 Low Sleep Clock Register
  fields as APB1LLPENR
0x174 C1_APB1HLPENR — RCC APB1 High Sleep Clock Register
  fields as APB1HLPENR
0x178 C1_APB2LPENR — RCC APB2 Sleep Clock Register
  fields as APB2LPENR
0x17C C1_APB4LPENR — RCC APB4 Sleep Clock Register
  fields as APB4LPENR
